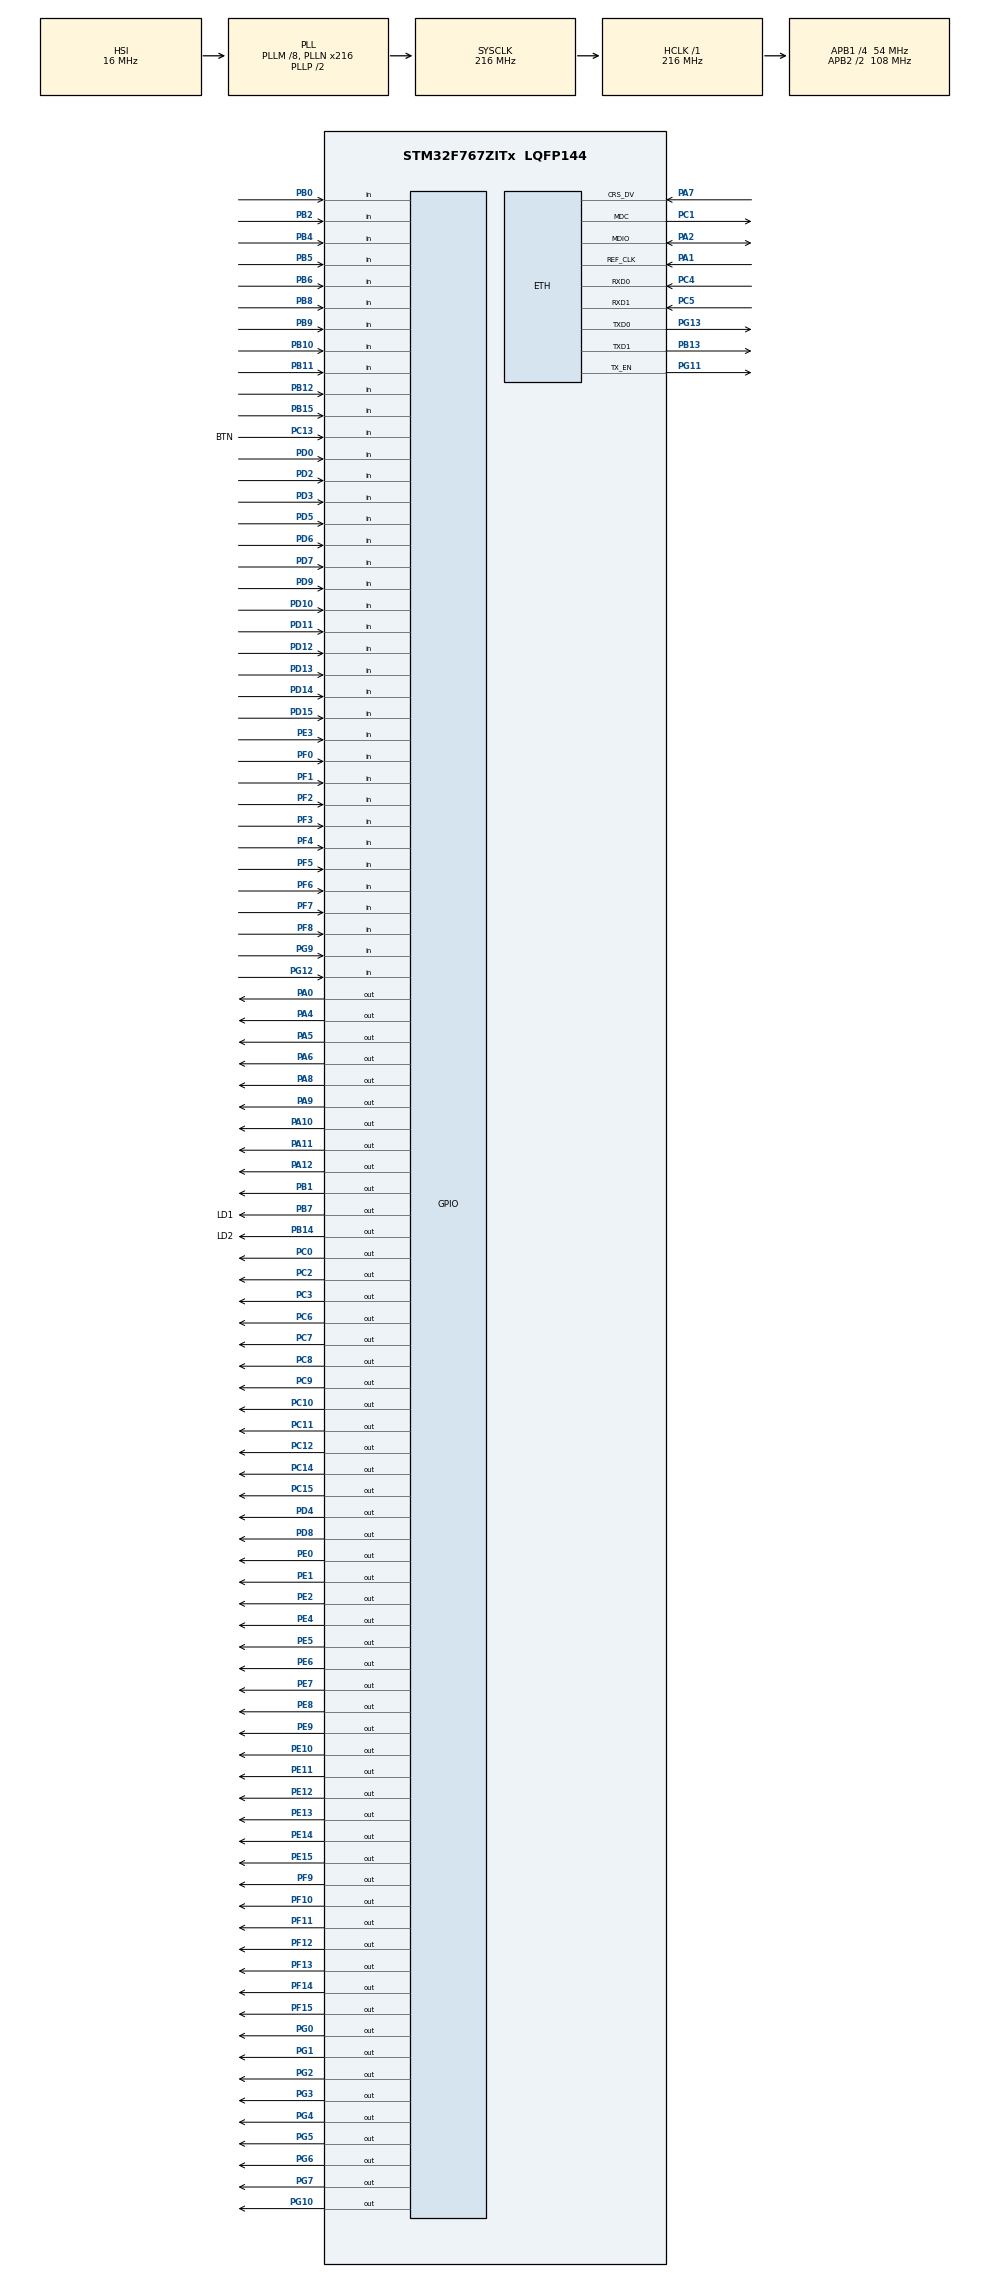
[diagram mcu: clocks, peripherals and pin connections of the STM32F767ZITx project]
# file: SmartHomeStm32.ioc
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CORTEX_M7.AccessPermission-Cortex_Memory_Protection_Unit_Region0_Settings=MPU_REGION_FULL_ACCESS
CORTEX_M7.BaseAddress-Cortex_Memory_Protection_Unit_Region0_Settings=0x2007c000
CORTEX_M7.CPU_DCache=Enabled
CORTEX_M7.CPU_ICache=Enabled
CORTEX_M7.DisableExec-Cortex_Memory_Protection_Unit_Region0_Settings=MPU_INSTRUCTION_ACCESS_DISABLE
CORTEX_M7.Enable-Cortex_Memory_Protection_Unit_Region0_Settings=MPU_REGION_ENABLE
CORTEX_M7.Enable-Cortex_Memory_Protection_Unit_Region1_Settings=__NULL
CORTEX_M7.IsShareable-Cortex_Memory_Protection_Unit_Region0_Settings=MPU_ACCESS_SHAREABLE
CORTEX_M7.MPU_Control=MPU_PRIVILEGED_DEFAULT
CORTEX_M7.PREFETCH_ENABLE=1
ETH.MediaInterface=HAL_ETH_RMII_MODE
FREERTOS.Tasks01=defaultTask,0,256,StartDefaultTask,Default,NULL,Dynamic,NULL,NULL
FREERTOS.configUSE_NEWLIB_REENTRANT=1
LWIP.BSP.number=1
LWIP.CMSIS_VERSION-Enabled=1
LWIP.GATEWAY_ADDRESS=192.168.001.001
LWIP.IP_ADDRESS=192.168.001.028
LWIP.LWIP_DHCP=0
LWIP.LWIP_HTTPD=0
LWIP.LWIP_NETIF_EXT_STATUS_CALLBACK=0
LWIP.LWIP_NETIF_LOOPBACK=1
LWIP.LWIP_NETIF_STATUS_CALLBACK=1
LWIP.LWIP_SOCKET=0
LWIP.LWIP_SOCKET_POLL=0
LWIP.LWIP_SOCKET_SELECT=0
LWIP.LWIP_UDP=1
LWIP.MEM_SIZE=10*1024
LWIP.NETMASK_ADDRESS=255.255.255.000
LWIP.Version=v2.1.2_Cube
LWIP0.BSP.STBoard=false
LWIP0.BSP.api=BSP_COMPONENT_DRIVER
LWIP0.BSP.component=LAN8742
LWIP0.BSP.instance=LAN8742
LWIP0.BSP.name=Driver_PHY
LWIP0.BSP.semaphore=S_LAN8742
LWIP0.BSP.solution=LAN8742
Mcu.Family=STM32F7
Mcu.Name=STM32F767ZITx
Mcu.Package=LQFP144
NVIC.ETH_IRQn=true\:5\:0\:false\:false\:true\:true\:false\:true\:true
NVIC.PriorityGroup=NVIC_PRIORITYGROUP_4
NVIC.TIM1_UP_TIM10_IRQn=true\:15\:0\:false\:false\:true\:false\:false\:true\:true
NVIC.TIM2_IRQn=true\:5\:0\:false\:false\:true\:true\:true\:true\:true
NVIC.TimeBase=TIM1_UP_TIM10_IRQn
NVIC.TimeBaseIP=TIM1
PA0/WKUP.Signal=GPIO_Output
PA1.Mode=RMII
PA1.Signal=ETH_REF_CLK
PA10.Signal=GPIO_Output
PA11.Signal=GPIO_Output
PA12.Signal=GPIO_Output
PA2.Mode=RMII
PA2.Signal=ETH_MDIO
PA4.Signal=GPIO_Output
PA5.Signal=GPIO_Output
PA6.Signal=GPIO_Output
PA7.Mode=RMII
PA7.Signal=ETH_CRS_DV
PA8.Signal=GPIO_Output
PA9.Signal=GPIO_Output
PB0.GPIO_PuPd=GPIO_PULLUP
PB0.Signal=GPIO_Input
PB1.Signal=GPIO_Output
PB10.GPIO_PuPd=GPIO_PULLUP
PB10.Signal=GPIO_Input
PB11.GPIO_PuPd=GPIO_PULLUP
PB11.Signal=GPIO_Input
PB12.GPIO_PuPd=GPIO_PULLUP
PB12.Signal=GPIO_Input
PB13.Mode=RMII
PB13.Signal=ETH_TXD1
PB14.GPIO_Label=LD2
PB14.Signal=GPIO_Output
PB15.GPIO_PuPd=GPIO_PULLUP
PB15.Signal=GPIO_Input
PB2.GPIO_PuPd=GPIO_PULLUP
PB2.Signal=GPIO_Input
PB3.Signal=SYS_JTDO-SWO
PB4.GPIO_PuPd=GPIO_PULLUP
PB4.Signal=GPIO_Input
PB5.GPIO_PuPd=GPIO_PULLUP
PB5.Signal=GPIO_Input
PB6.GPIO_PuPd=GPIO_PULLUP
PB6.Signal=GPIO_Input
PB7.GPIO_Label=LD1
PB7.Signal=GPIO_Output
PB8.GPIO_PuPd=GPIO_PULLUP
PB8.Signal=GPIO_Input
PB9.GPIO_PuPd=GPIO_PULLUP
PB9.Signal=GPIO_Input
PC0.Signal=GPIO_Output
PC1.Mode=RMII
PC1.Signal=ETH_MDC
PC10.Signal=GPIO_Output
PC11.Signal=GPIO_Output
PC12.Signal=GPIO_Output
PC13.GPIO_Label=BTN
PC13.GPIO_PuPd=GPIO_PULLUP
PC13.Signal=GPIO_Input
PC14/OSC32_IN.Signal=GPIO_Output
PC15/OSC32_OUT.Signal=GPIO_Output
PC2.Signal=GPIO_Output
PC3.Signal=GPIO_Output
PC4.Mode=RMII
PC4.Signal=ETH_RXD0
PC5.Mode=RMII
PC5.Signal=ETH_RXD1
PC6.Signal=GPIO_Output
PC7.Signal=GPIO_Output
PC8.Signal=GPIO_Output
PC9.Signal=GPIO_Output
PD0.GPIO_PuPd=GPIO_PULLUP
PD0.Signal=GPIO_Input
PD10.GPIO_PuPd=GPIO_PULLUP
PD10.Signal=GPIO_Input
PD11.GPIO_PuPd=GPIO_PULLUP
PD11.Signal=GPIO_Input
PD12.GPIO_PuPd=GPIO_PULLUP
PD12.Signal=GPIO_Input
PD13.GPIO_PuPd=GPIO_PULLUP
PD13.Signal=GPIO_Input
PD14.GPIO_PuPd=GPIO_PULLUP
PD14.Signal=GPIO_Input
PD15.GPIO_PuPd=GPIO_PULLUP
PD15.Signal=GPIO_Input
PD2.GPIO_PuPd=GPIO_PULLUP
PD2.Signal=GPIO_Input
PD3.GPIO_PuPd=GPIO_PULLUP
PD3.Signal=GPIO_Input
PD4.Signal=GPIO_Output
PD5.GPIO_PuPd=GPIO_PULLUP
PD5.Signal=GPIO_Input
PD6.GPIO_PuPd=GPIO_PULLUP
PD6.Signal=GPIO_Input
PD7.GPIO_PuPd=GPIO_PULLUP
PD7.Signal=GPIO_Input
PD8.Signal=GPIO_Output
PD9.GPIO_PuPd=GPIO_PULLUP
PD9.Signal=GPIO_Input
PE0.Signal=GPIO_Output
PE1.Signal=GPIO_Output
PE10.Signal=GPIO_Output
PE11.Signal=GPIO_Output
PE12.Signal=GPIO_Output
PE13.Signal=GPIO_Output
PE14.Signal=GPIO_Output
PE15.Signal=GPIO_Output
PE2.Signal=GPIO_Output
PE3.GPIO_PuPd=GPIO_PULLUP
PE3.Signal=GPIO_Input
PE4.Signal=GPIO_Output
PE5.Signal=GPIO_Output
PE6.Signal=GPIO_Output
PE7.Signal=GPIO_Output
PE8.Signal=GPIO_Output
PE9.Signal=GPIO_Output
PF0.GPIO_PuPd=GPIO_PULLUP
PF0.Signal=GPIO_Input
PF1.GPIO_PuPd=GPIO_PULLUP
PF1.Signal=GPIO_Input
PF10.Signal=GPIO_Output
PF11.Signal=GPIO_Output
PF12.Signal=GPIO_Output
PF13.Signal=GPIO_Output
PF14.Signal=GPIO_Output
PF15.Signal=GPIO_Output
PF2.GPIO_PuPd=GPIO_PULLUP
PF2.Signal=GPIO_Input
PF3.GPIO_PuPd=GPIO_PULLUP
PF3.Signal=GPIO_Input
PF4.GPIO_PuPd=GPIO_PULLUP
PF4.Signal=GPIO_Input
PF5.GPIO_PuPd=GPIO_PULLUP
PF5.Signal=GPIO_Input
PF6.GPIO_PuPd=GPIO_PULLUP
PF6.Signal=GPIO_Input
PF7.GPIO_PuPd=GPIO_PULLUP
PF7.Signal=GPIO_Input
PF8.GPIO_PuPd=GPIO_PULLUP
PF8.Signal=GPIO_Input
PF9.Signal=GPIO_Output
PG0.Signal=GPIO_Output
PG1.Signal=GPIO_Output
PG10.Signal=GPIO_Output
PG11.Mode=RMII
PG11.Signal=ETH_TX_EN
PG12.GPIO_PuPd=GPIO_PULLUP
PG12.Signal=GPIO_Input
PG13.Mode=RMII
PG13.Signal=ETH_TXD0
PG2.Signal=GPIO_Output
PG3.Signal=GPIO_Output
PG4.Signal=GPIO_Output
PG5.Signal=GPIO_Output
PG6.Signal=GPIO_Output
PG7.Signal=GPIO_Output
PG9.GPIO_PuPd=GPIO_PULLUP
PG9.Signal=GPIO_Input
PH0/OSC_IN.Mode=HSE-External-Oscillator
PH0/OSC_IN.Signal=RCC_OSC_IN
PH1/OSC_OUT.Mode=HSE-External-Oscillator
PH1/OSC_OUT.Signal=RCC_OSC_OUT
ProjectManager.HeapSize=0x200
ProjectManager.StackSize=0x400
ProjectManager.TargetToolchain=STM32CubeIDE
RCC.AHBFreq_Value=216000000
RCC.APB1CLKDivider=RCC_HCLK_DIV4
RCC.APB1Freq_Value=54000000
RCC.APB1TimFreq_Value=108000000
RCC.APB2CLKDivider=RCC_HCLK_DIV2
RCC.APB2Freq_Value=108000000
RCC.APB2TimFreq_Value=216000000
RCC.CortexFreq_Value=216000000
RCC.HCLKFreq_Value=216000000
RCC.HSE_VALUE=25000000
RCC.HSI_VALUE=16000000
RCC.LSE_VALUE=32768
RCC.PLLM=8
RCC.PLLN=216
RCC.SYSCLKFreq_VALUE=216000000
RCC.SYSCLKSource=RCC_SYSCLKSOURCE_PLLCLK
RCC.USBFreq_Value=216000000
RCC.VCOOutputFreq_Value=432000000
TIM2.Period=60000000-1
TIM2.Prescaler=108-1
VP_FREERTOS_VS_CMSIS_V1.Mode=CMSIS_V1
VP_LWIP_VS_Enabled.Mode=Enabled
VP_RTC_VS_RTC_Activate.Mode=RTC_Enabled
VP_RTC_VS_RTC_Calendar.Mode=RTC_Calendar
VP_SYS_VS_tim1.Mode=TIM1
VP_TIM2_VS_ClockSourceINT.Mode=Internal
board=custom

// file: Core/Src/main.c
/* USER CODE BEGIN Header */
/**
 ******************************************************************************
 * @file           : main.c
 * @brief          : Main program body
 ******************************************************************************
 * @attention
 *
 * Copyright (c) 2023 STMicroelectronics.
 * All rights reserved.
 *
 * This software is licensed under terms that can be found in the LICENSE file
 * in the root directory of this software component.
 * If no LICENSE file comes with this software, it is provided AS-IS.
 *
 ******************************************************************************
 */
/* USER CODE END Header */
#include "main.h"
#include "cmsis_os.h"
#include "lwip.h"

/* USER CODE BEGIN Includes */

#include "entry.hpp"
#include <stdbool.h>
/* USER CODE END Includes */

RTC_HandleTypeDef hrtc;

TIM_HandleTypeDef htim2;

osThreadId defaultTaskHandle;

void SystemClock_Config(void);
static void MPU_Config(void);
static void MX_GPIO_Init(void);
static void MX_RTC_Init(void);
static void MX_TIM2_Init(void);
void StartDefaultTask(void const * argument);

int main(void)
{

  /* MPU Configuration--------------------------------------------------------*/
  MPU_Config();

  /* Enable I-Cache---------------------------------------------------------*/
  SCB_EnableICache();

  /* Enable D-Cache---------------------------------------------------------*/
  SCB_EnableDCache();

  /* MCU Configuration--------------------------------------------------------*/

  /* Reset of all peripherals, Initializes the Flash interface and the Systick. */
  HAL_Init();

  /* Configure the system clock */
  SystemClock_Config();

  /* Initialize all configured peripherals */
  MX_GPIO_Init();
  MX_RTC_Init();
  MX_TIM2_Init();
  /* USER CODE BEGIN 2 */

	HAL_TIM_Base_Start_IT(&htim2);
  /* USER CODE END 2 */

  /* Create the thread(s) */
  /* definition and creation of defaultTask */
  osThreadDef(defaultTask, StartDefaultTask, osPriorityNormal, 0, 256);
  defaultTaskHandle = osThreadCreate(osThread(defaultTask), NULL);

  /* Start scheduler */
  osKernelStart();
  /* We should never get here as control is now taken by the scheduler */
  /* Infinite loop */
	while (1)
	{

	}
}

void SystemClock_Config(void)
{
  RCC_OscInitTypeDef RCC_OscInitStruct = {0};
  RCC_ClkInitTypeDef RCC_ClkInitStruct = {0};

  /** Configure the main internal regulator output voltage
  */
  __HAL_RCC_PWR_CLK_ENABLE();
  __HAL_PWR_VOLTAGESCALING_CONFIG(PWR_REGULATOR_VOLTAGE_SCALE1);

  /** Initializes the RCC Oscillators according to the specified parameters
  * in the RCC_OscInitTypeDef structure.
  */
  RCC_OscInitStruct.OscillatorType = RCC_OSCILLATORTYPE_HSI|RCC_OSCILLATORTYPE_LSI;
  RCC_OscInitStruct.HSIState = RCC_HSI_ON;
  RCC_OscInitStruct.HSICalibrationValue = RCC_HSICALIBRATION_DEFAULT;
  RCC_OscInitStruct.LSIState = RCC_LSI_ON;
  RCC_OscInitStruct.PLL.PLLState = RCC_PLL_ON;
  RCC_OscInitStruct.PLL.PLLSource = RCC_PLLSOURCE_HSI;
  RCC_OscInitStruct.PLL.PLLM = 8;
  RCC_OscInitStruct.PLL.PLLN = 216;
  RCC_OscInitStruct.PLL.PLLP = RCC_PLLP_DIV2;
  RCC_OscInitStruct.PLL.PLLQ = 2;
  RCC_OscInitStruct.PLL.PLLR = 2;
  if (HAL_RCC_OscConfig(&RCC_OscInitStruct) != HAL_OK)
  {
    Error_Handler();
  }

  /** Activate the Over-Drive mode
  */
  if (HAL_PWREx_EnableOverDrive() != HAL_OK)
  {
    Error_Handler();
  }

  /** Initializes the CPU, AHB and APB buses clocks
  */
  RCC_ClkInitStruct.ClockType = RCC_CLOCKTYPE_HCLK|RCC_CLOCKTYPE_SYSCLK
                              |RCC_CLOCKTYPE_PCLK1|RCC_CLOCKTYPE_PCLK2;
  RCC_ClkInitStruct.SYSCLKSource = RCC_SYSCLKSOURCE_PLLCLK;
  RCC_ClkInitStruct.AHBCLKDivider = RCC_SYSCLK_DIV1;
  RCC_ClkInitStruct.APB1CLKDivider = RCC_HCLK_DIV4;
  RCC_ClkInitStruct.APB2CLKDivider = RCC_HCLK_DIV2;

  if (HAL_RCC_ClockConfig(&RCC_ClkInitStruct, FLASH_LATENCY_7) != HAL_OK)
  {
    Error_Handler();
  }
}

static void MX_RTC_Init(void)
{

  RTC_TimeTypeDef sTime = {0};
  RTC_DateTypeDef sDate = {0};

  /** Initialize RTC Only
  */
  hrtc.Instance = RTC;
  hrtc.Init.HourFormat = RTC_HOURFORMAT_24;
  hrtc.Init.AsynchPrediv = 127;
  hrtc.Init.SynchPrediv = 255;
  hrtc.Init.OutPut = RTC_OUTPUT_DISABLE;
  hrtc.Init.OutPutPolarity = RTC_OUTPUT_POLARITY_HIGH;
  hrtc.Init.OutPutType = RTC_OUTPUT_TYPE_OPENDRAIN;
  if (HAL_RTC_Init(&hrtc) != HAL_OK)
  {
    Error_Handler();
  }

  /** Initialize RTC and set the Time and Date
  */
  sTime.Hours = 0x0;
  sTime.Minutes = 0x0;
  sTime.Seconds = 0x0;
  sTime.DayLightSaving = RTC_DAYLIGHTSAVING_NONE;
  sTime.StoreOperation = RTC_STOREOPERATION_RESET;
  if (HAL_RTC_SetTime(&hrtc, &sTime, RTC_FORMAT_BCD) != HAL_OK)
  {
    Error_Handler();
  }
  sDate.WeekDay = RTC_WEEKDAY_MONDAY;
  sDate.Month = RTC_MONTH_JANUARY;
  sDate.Date = 0x1;
  sDate.Year = 0x0;

  if (HAL_RTC_SetDate(&hrtc, &sDate, RTC_FORMAT_BCD) != HAL_OK)
  {
    Error_Handler();
  }

}

static void MX_TIM2_Init(void)
{

  TIM_ClockConfigTypeDef sClockSourceConfig = {0};
  TIM_MasterConfigTypeDef sMasterConfig = {0};

  htim2.Instance = TIM2;
  htim2.Init.Prescaler = 108-1;
  htim2.Init.CounterMode = TIM_COUNTERMODE_UP;
  htim2.Init.Period = 60000000-1;
  htim2.Init.ClockDivision = TIM_CLOCKDIVISION_DIV1;
  htim2.Init.AutoReloadPreload = TIM_AUTORELOAD_PRELOAD_DISABLE;
  if (HAL_TIM_Base_Init(&htim2) != HAL_OK)
  {
    Error_Handler();
  }
  sClockSourceConfig.ClockSource = TIM_CLOCKSOURCE_INTERNAL;
  if (HAL_TIM_ConfigClockSource(&htim2, &sClockSourceConfig) != HAL_OK)
  {
    Error_Handler();
  }
  sMasterConfig.MasterOutputTrigger = TIM_TRGO_RESET;
  sMasterConfig.MasterSlaveMode = TIM_MASTERSLAVEMODE_DISABLE;
  if (HAL_TIMEx_MasterConfigSynchronization(&htim2, &sMasterConfig) != HAL_OK)
  {
    Error_Handler();
  }

}

static void MX_GPIO_Init(void)
{
  GPIO_InitTypeDef GPIO_InitStruct = {0};

  /* GPIO Ports Clock Enable */
  __HAL_RCC_GPIOE_CLK_ENABLE();
  __HAL_RCC_GPIOC_CLK_ENABLE();
  __HAL_RCC_GPIOF_CLK_ENABLE();
  __HAL_RCC_GPIOH_CLK_ENABLE();
  __HAL_RCC_GPIOA_CLK_ENABLE();
  __HAL_RCC_GPIOB_CLK_ENABLE();
  __HAL_RCC_GPIOG_CLK_ENABLE();
  __HAL_RCC_GPIOD_CLK_ENABLE();

  /*Configure GPIO pin Output Level */
  HAL_GPIO_WritePin(GPIOE, GPIO_PIN_2|GPIO_PIN_4|GPIO_PIN_5|GPIO_PIN_6
                          |GPIO_PIN_7|GPIO_PIN_8|GPIO_PIN_9|GPIO_PIN_10
                          |GPIO_PIN_11|GPIO_PIN_12|GPIO_PIN_13|GPIO_PIN_14
                          |GPIO_PIN_15|GPIO_PIN_0|GPIO_PIN_1, GPIO_PIN_RESET);

  /*Configure GPIO pin Output Level */
  HAL_GPIO_WritePin(GPIOC, GPIO_PIN_14|GPIO_PIN_15|GPIO_PIN_0|GPIO_PIN_2
                          |GPIO_PIN_3|GPIO_PIN_6|GPIO_PIN_7|GPIO_PIN_8
                          |GPIO_PIN_9|GPIO_PIN_10|GPIO_PIN_11|GPIO_PIN_12, GPIO_PIN_RESET);

  /*Configure GPIO pin Output Level */
  HAL_GPIO_WritePin(GPIOF, GPIO_PIN_9|GPIO_PIN_10|GPIO_PIN_11|GPIO_PIN_12
                          |GPIO_PIN_13|GPIO_PIN_14|GPIO_PIN_15, GPIO_PIN_RESET);

  /*Configure GPIO pin Output Level */
  HAL_GPIO_WritePin(GPIOA, GPIO_PIN_0|GPIO_PIN_4|GPIO_PIN_5|GPIO_PIN_6
                          |GPIO_PIN_8|GPIO_PIN_9|GPIO_PIN_10|GPIO_PIN_11
                          |GPIO_PIN_12, GPIO_PIN_RESET);

  /*Configure GPIO pin Output Level */
  HAL_GPIO_WritePin(GPIOB, GPIO_PIN_1|LD2_Pin|LD1_Pin, GPIO_PIN_RESET);

  /*Configure GPIO pin Output Level */
  HAL_GPIO_WritePin(GPIOG, GPIO_PIN_0|GPIO_PIN_1|GPIO_PIN_2|GPIO_PIN_3
                          |GPIO_PIN_4|GPIO_PIN_5|GPIO_PIN_6|GPIO_PIN_7
                          |GPIO_PIN_10, GPIO_PIN_RESET);

  /*Configure GPIO pin Output Level */
  HAL_GPIO_WritePin(GPIOD, GPIO_PIN_8|GPIO_PIN_4, GPIO_PIN_RESET);

  /*Configure GPIO pins : PE2 PE4 PE5 PE6
                           PE7 PE8 PE9 PE10
                           PE11 PE12 PE13 PE14
                           PE15 PE0 PE1 */
  GPIO_InitStruct.Pin = GPIO_PIN_2|GPIO_PIN_4|GPIO_PIN_5|GPIO_PIN_6
                          |GPIO_PIN_7|GPIO_PIN_8|GPIO_PIN_9|GPIO_PIN_10
                          |GPIO_PIN_11|GPIO_PIN_12|GPIO_PIN_13|GPIO_PIN_14
                          |GPIO_PIN_15|GPIO_PIN_0|GPIO_PIN_1;
  GPIO_InitStruct.Mode = GPIO_MODE_OUTPUT_PP;
  GPIO_InitStruct.Pull = GPIO_NOPULL;
  GPIO_InitStruct.Speed = GPIO_SPEED_FREQ_LOW;
  HAL_GPIO_Init(GPIOE, &GPIO_InitStruct);

  /*Configure GPIO pin : PE3 */
  GPIO_InitStruct.Pin = GPIO_PIN_3;
  GPIO_InitStruct.Mode = GPIO_MODE_INPUT;
  GPIO_InitStruct.Pull = GPIO_PULLUP;
  HAL_GPIO_Init(GPIOE, &GPIO_InitStruct);

  /*Configure GPIO pin : BTN_Pin */
  GPIO_InitStruct.Pin = BTN_Pin;
  GPIO_InitStruct.Mode = GPIO_MODE_INPUT;
  GPIO_InitStruct.Pull = GPIO_PULLUP;
  HAL_GPIO_Init(BTN_GPIO_Port, &GPIO_InitStruct);

  /*Configure GPIO pins : PC14 PC15 PC0 PC2
                           PC3 PC6 PC7 PC8
                           PC9 PC10 PC11 PC12 */
  GPIO_InitStruct.Pin = GPIO_PIN_14|GPIO_PIN_15|GPIO_PIN_0|GPIO_PIN_2
                          |GPIO_PIN_3|GPIO_PIN_6|GPIO_PIN_7|GPIO_PIN_8
                          |GPIO_PIN_9|GPIO_PIN_10|GPIO_PIN_11|GPIO_PIN_12;
  GPIO_InitStruct.Mode = GPIO_MODE_OUTPUT_PP;
  GPIO_InitStruct.Pull = GPIO_NOPULL;
  GPIO_InitStruct.Speed = GPIO_SPEED_FREQ_LOW;
  HAL_GPIO_Init(GPIOC, &GPIO_InitStruct);

  /*Configure GPIO pins : PF0 PF1 PF2 PF3
                           PF4 PF5 PF6 PF7
                           PF8 */
  GPIO_InitStruct.Pin = GPIO_PIN_0|GPIO_PIN_1|GPIO_PIN_2|GPIO_PIN_3
                          |GPIO_PIN_4|GPIO_PIN_5|GPIO_PIN_6|GPIO_PIN_7
                          |GPIO_PIN_8;
  GPIO_InitStruct.Mode = GPIO_MODE_INPUT;
  GPIO_InitStruct.Pull = GPIO_PULLUP;
  HAL_GPIO_Init(GPIOF, &GPIO_InitStruct);

  /*Configure GPIO pins : PF9 PF10 PF11 PF12
                           PF13 PF14 PF15 */
  GPIO_InitStruct.Pin = GPIO_PIN_9|GPIO_PIN_10|GPIO_PIN_11|GPIO_PIN_12
                          |GPIO_PIN_13|GPIO_PIN_14|GPIO_PIN_15;
  GPIO_InitStruct.Mode = GPIO_MODE_OUTPUT_PP;
  GPIO_InitStruct.Pull = GPIO_NOPULL;
  GPIO_InitStruct.Speed = GPIO_SPEED_FREQ_LOW;
  HAL_GPIO_Init(GPIOF, &GPIO_InitStruct);

  /*Configure GPIO pins : PA0 PA4 PA5 PA6
                           PA8 PA9 PA10 PA11
                           PA12 */
  GPIO_InitStruct.Pin = GPIO_PIN_0|GPIO_PIN_4|GPIO_PIN_5|GPIO_PIN_6
                          |GPIO_PIN_8|GPIO_PIN_9|GPIO_PIN_10|GPIO_PIN_11
                          |GPIO_PIN_12;
  GPIO_InitStruct.Mode = GPIO_MODE_OUTPUT_PP;
  GPIO_InitStruct.Pull = GPIO_NOPULL;
  GPIO_InitStruct.Speed = GPIO_SPEED_FREQ_LOW;
  HAL_GPIO_Init(GPIOA, &GPIO_InitStruct);

  /*Configure GPIO pins : PB0 PB2 PB10 PB11
                           PB12 PB15 PB4 PB5
                           PB6 PB8 PB9 */
  GPIO_InitStruct.Pin = GPIO_PIN_0|GPIO_PIN_2|GPIO_PIN_10|GPIO_PIN_11
                          |GPIO_PIN_12|GPIO_PIN_15|GPIO_PIN_4|GPIO_PIN_5
                          |GPIO_PIN_6|GPIO_PIN_8|GPIO_PIN_9;
  GPIO_InitStruct.Mode = GPIO_MODE_INPUT;
  GPIO_InitStruct.Pull = GPIO_PULLUP;
  HAL_GPIO_Init(GPIOB, &GPIO_InitStruct);

  /*Configure GPIO pins : PB1 LD2_Pin LD1_Pin */
  GPIO_InitStruct.Pin = GPIO_PIN_1|LD2_Pin|LD1_Pin;
  GPIO_InitStruct.Mode = GPIO_MODE_OUTPUT_PP;
  GPIO_InitStruct.Pull = GPIO_NOPULL;
  GPIO_InitStruct.Speed = GPIO_SPEED_FREQ_LOW;
  HAL_GPIO_Init(GPIOB, &GPIO_InitStruct);

  /*Configure GPIO pins : PG0 PG1 PG2 PG3
                           PG4 PG5 PG6 PG7
                           PG10 */
  GPIO_InitStruct.Pin = GPIO_PIN_0|GPIO_PIN_1|GPIO_PIN_2|GPIO_PIN_3
                          |GPIO_PIN_4|GPIO_PIN_5|GPIO_PIN_6|GPIO_PIN_7
                          |GPIO_PIN_10;
  GPIO_InitStruct.Mode = GPIO_MODE_OUTPUT_PP;
  GPIO_InitStruct.Pull = GPIO_NOPULL;
  GPIO_InitStruct.Speed = GPIO_SPEED_FREQ_LOW;
  HAL_GPIO_Init(GPIOG, &GPIO_InitStruct);

  /*Configure GPIO pins : PD8 PD4 */
  GPIO_InitStruct.Pin = GPIO_PIN_8|GPIO_PIN_4;
  GPIO_InitStruct.Mode = GPIO_MODE_OUTPUT_PP;
  GPIO_InitStruct.Pull = GPIO_NOPULL;
  GPIO_InitStruct.Speed = GPIO_SPEED_FREQ_LOW;
  HAL_GPIO_Init(GPIOD, &GPIO_InitStruct);

  /*Configure GPIO pins : PD9 PD10 PD11 PD12
                           PD13 PD14 PD15 PD0
                           PD2 PD3 PD5 PD6
                           PD7 */
  GPIO_InitStruct.Pin = GPIO_PIN_9|GPIO_PIN_10|GPIO_PIN_11|GPIO_PIN_12
                          |GPIO_PIN_13|GPIO_PIN_14|GPIO_PIN_15|GPIO_PIN_0
                          |GPIO_PIN_2|GPIO_PIN_3|GPIO_PIN_5|GPIO_PIN_6
                          |GPIO_PIN_7;
  GPIO_InitStruct.Mode = GPIO_MODE_INPUT;
  GPIO_InitStruct.Pull = GPIO_PULLUP;
  HAL_GPIO_Init(GPIOD, &GPIO_InitStruct);

  /*Configure GPIO pins : PG9 PG12 */
  GPIO_InitStruct.Pin = GPIO_PIN_9|GPIO_PIN_12;
  GPIO_InitStruct.Mode = GPIO_MODE_INPUT;
  GPIO_InitStruct.Pull = GPIO_PULLUP;
  HAL_GPIO_Init(GPIOG, &GPIO_InitStruct);

}

/* USER CODE BEGIN 4 */
void http_thread(void *arg)
{
	http_listen();
}

void http_server_init()
{
	sys_thread_new("http_thread", http_thread, NULL, DEFAULT_THREAD_STACKSIZE, osPriorityNormal);
}

void SetTime(int hours, int minutes, int seconds, int day, int month, int year)
{
	RTC_TimeTypeDef sTime = {0};
	RTC_DateTypeDef sDate = {0};

	sTime.Hours = hours;
	sTime.Minutes = minutes;
	sTime.Seconds = seconds;
	sTime.DayLightSaving = RTC_DAYLIGHTSAVING_NONE;
	sTime.StoreOperation = RTC_STOREOPERATION_RESET;
	if (HAL_RTC_SetTime(&hrtc, &sTime, RTC_FORMAT_BIN) != HAL_OK)
	{
		Error_Handler();
	}

	sDate.Date = day;
	sDate.Year = year;

	switch (month)
	{
	case 1:
		sDate.Month = RTC_MONTH_JANUARY;
		break;
	case 2:
		sDate.Month = RTC_MONTH_FEBRUARY;
		break;
	case 3:
		sDate.Month = RTC_MONTH_MARCH;
		break;
	case 4:
		sDate.Month = RTC_MONTH_APRIL;
		break;
	case 5:
		sDate.Month = RTC_MONTH_MAY;
		break;
	case 6:
		sDate.Month = RTC_MONTH_JUNE;
		break;
	case 7:
		sDate.Month = RTC_MONTH_JULY;
		break;
	case 8:
		sDate.Month = RTC_MONTH_AUGUST;
		break;
	case 9:
		sDate.Month = RTC_MONTH_SEPTEMBER;
		break;
	case 10:
		sDate.Month = RTC_MONTH_OCTOBER;
		break;
	case 11:
		sDate.Month = RTC_MONTH_NOVEMBER;
		break;
	case 12:
		sDate.Month = RTC_MONTH_DECEMBER;
		break;
	}

	if (HAL_RTC_SetDate(&hrtc, &sDate, RTC_FORMAT_BIN) != HAL_OK)
	{
		Error_Handler();
	}
}

const char * GetTime()
{
	RTC_TimeTypeDef sTime = {0};
	RTC_DateTypeDef sDate = {0};

	if (HAL_RTC_GetTime(&hrtc, &sTime, RTC_FORMAT_BIN) != HAL_OK)
	{
		Error_Handler();
	}
	if (HAL_RTC_GetDate(&hrtc, &sDate, RTC_FORMAT_BIN) != HAL_OK)
	{
		Error_Handler();
	}

	return TimeToString(sTime, sDate);
}

int _write(int file, char *ptr, int len)
{
	int DataIdx;

	for(DataIdx = 0; DataIdx < len; DataIdx++)
	{
		ITM_SendChar(*ptr++);
	}

	return len;
}
/* USER CODE END 4 */

void StartDefaultTask(void const * argument)
{
  /* init code for LWIP */
  MX_LWIP_Init();
  /* USER CODE BEGIN 5 */
	http_server_init();
	/* Infinite loop */
	for(;;)
	{
		CheckAndSwitchLights();
		osDelay(1);
	}
  /* USER CODE END 5 */
}

/* MPU Configuration */

void MPU_Config(void)
{
  MPU_Region_InitTypeDef MPU_InitStruct = {0};

  /* Disables the MPU */
  HAL_MPU_Disable();

  /** Initializes and configures the Region and the memory to be protected
  */
  MPU_InitStruct.Enable = MPU_REGION_ENABLE;
  MPU_InitStruct.Number = MPU_REGION_NUMBER0;
  MPU_InitStruct.BaseAddress = 0x2007c000;
  MPU_InitStruct.Size = MPU_REGION_SIZE_32B;
  MPU_InitStruct.SubRegionDisable = 0x0;
  MPU_InitStruct.TypeExtField = MPU_TEX_LEVEL0;
  MPU_InitStruct.AccessPermission = MPU_REGION_FULL_ACCESS;
  MPU_InitStruct.DisableExec = MPU_INSTRUCTION_ACCESS_DISABLE;
  MPU_InitStruct.IsShareable = MPU_ACCESS_SHAREABLE;
  MPU_InitStruct.IsCacheable = MPU_ACCESS_NOT_CACHEABLE;
  MPU_InitStruct.IsBufferable = MPU_ACCESS_NOT_BUFFERABLE;

  HAL_MPU_ConfigRegion(&MPU_InitStruct);
  /* Enables the MPU */
  HAL_MPU_Enable(MPU_PRIVILEGED_DEFAULT);

}

void HAL_TIM_PeriodElapsedCallback(TIM_HandleTypeDef *htim)
{
  if (htim->Instance == TIM1) {
    HAL_IncTick();
  }
  /* USER CODE BEGIN Callback 1 */
	if (htim == &htim2)
	{
		RTC_TimeTypeDef sTime = {0};
		RTC_DateTypeDef sDate = {0};

		if (HAL_RTC_GetTime(&hrtc, &sTime, RTC_FORMAT_BIN) == HAL_OK &&
				HAL_RTC_GetDate(&hrtc, &sDate, RTC_FORMAT_BIN) == HAL_OK)
		{
			TriggerScheduler(sTime, sDate);
		}
	}
  /* USER CODE END Callback 1 */
}

void Error_Handler(void)
{
	__disable_irq();
	while (1)
	{
	}
}
